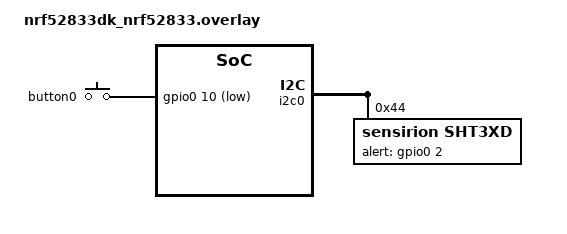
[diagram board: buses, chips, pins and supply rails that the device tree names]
// To get started, press Ctrl+Space (or Option+Esc) to bring up the completion menu and view the available nodes.

// You can also use the buttons in the sidebar to perform actions on nodes.
// Actions currently available include:

// * Enabling / disabling the node
// * Adding the bus to a bus
// * Removing the node
// * Connecting ADC channels

// For more help, browse the DeviceTree documentation at https://docs.zephyrproject.org/latest/guides/dts/index.html
// You can also visit the nRF DeviceTree extension documentation at https://docs.nordicsemi.com/bundle/nrf-connect-vscode/page/guides/ncs_configure_app.html#devicetree-support-in-the-extension
&i2c0 { /* SDA 0, SCL 1 */
	sht3xd@44 {
		compatible = "sensirion,sht3xd";
		reg = <0x44>;
		alert-gpios = <&gpio0 2 GPIO_ACTIVE_HIGH>;
	};
};

&i2c0_default {
	group1 {
		psels = <NRF_PSEL(TWIM_SDA, 0, 11)>, <NRF_PSEL(TWIM_SCL, 1, 9)>;
	};
};

&button0 {
	gpios = <&gpio0 10 (GPIO_ACTIVE_LOW | GPIO_PULL_UP)>;
};
